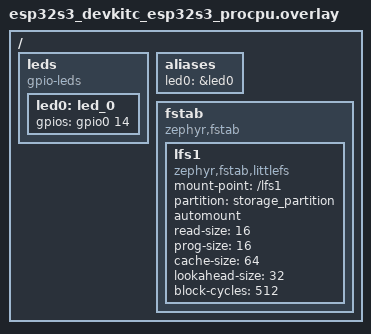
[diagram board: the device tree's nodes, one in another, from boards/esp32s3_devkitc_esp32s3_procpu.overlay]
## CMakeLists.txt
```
# Copyright (c) 2025 Golioth, Inc.
#
# SPDX-License-Identifier: Apache-2.0

cmake_minimum_required(VERSION 3.20.0)

find_package(Zephyr REQUIRED HINTS $ENV{ZEPHYR_BASE})
project(ble_gatt_example)

target_sources(app PRIVATE
  src/main.c
  src/credentials.c
  src/fatal_error.c
  src/fw_update.c
  src/ble_peripheral.c
)
```

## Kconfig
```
# Copyright (c) 2025 Golioth, Inc.
#
# SPDX-License-Identifier: Apache-2.0

config NCS_APPLICATION_BOOT_BANNER_STRING
    string
    default "Pouch BLE GATT Example"

source "$ZEPHYR_BASE/Kconfig"

config EXAMPLE_SYNC_PERIOD_S
    int "Sync Period"
    default 20
    help
      The time, in seconds, after a sync to wait before requesting a sync from
      a gateway.

config EXAMPLE_CREDENTIALS_DIR
    string "Directory containing credentials"
    default "/lfs1/credentials"
    help
      Directory on mounted file system containing credentials.
```

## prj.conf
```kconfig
# Copyright (c) 2025 Golioth, Inc.
#
# SPDX-License-Identifier: Apache-2.0

CONFIG_BT=y
CONFIG_BT_SMP=y
CONFIG_BT_PERIPHERAL=y
CONFIG_BT_DEVICE_NAME="Golioth"
CONFIG_BT_DEVICE_APPEARANCE=768

CONFIG_BT_BUF_ACL_TX_SIZE=251
CONFIG_BT_BUF_ACL_RX_SIZE=251
CONFIG_BT_L2CAP_TX_MTU=247

# This allows centrals that connect using Just Works authentication
# to re-pair. This can allow attackers to force a device to forget
# a legitimate bond. In production applications, we recommend using
# authenticated pairing, or if that is not an option, to limit the
# times when pairing is possible (e.g. by requiring user interaction
# to forget bonds or to enter pairing mode).
# We enable this option in the example app because in the absence of
# authenticated connections or another method for forcing the deletion
# of bond data, Centrals that lose their bonding information will be
# unable to reconnect.
CONFIG_BT_SMP_ALLOW_UNAUTH_OVERWRITE=y

# This is needed due to an off-by-one error in Kconfig defaults
CONFIG_BT_CTLR_DATA_LENGTH_MAX=251

CONFIG_BT_RX_STACK_SIZE=4096

CONFIG_MAIN_STACK_SIZE=4096

CONFIG_MBEDTLS_HEAP_SIZE=9192

# This option is implied by BT_SMP and breaks secp384r1 support
CONFIG_MBEDTLS_PSA_P256M_DRIVER_ENABLED=n

# Turn off default options to reduce ROM usage
CONFIG_MBEDTLS_PKCS5_C=n

CONFIG_LOG=y
CONFIG_ZCBOR=y
CONFIG_REBOOT=y
CONFIG_SHELL=y

CONFIG_POUCH=y
CONFIG_POUCH_TRANSPORT_BLE_GATT=y

CONFIG_GOLIOTH=y
CONFIG_GOLIOTH_SETTINGS=y
CONFIG_GOLIOTH_OTA=y

# Enable flash operations
CONFIG_FLASH=y
CONFIG_FLASH_MAP=y

# Enable the LittleFS file system
CONFIG_FILE_SYSTEM=y
CONFIG_FILE_SYSTEM_LITTLEFS=y
CONFIG_FILE_SYSTEM_SHELL=y

CONFIG_MCUMGR=y

# Enable console with mcumgr pass through
CONFIG_CONSOLE=y
CONFIG_UART_CONSOLE=y
CONFIG_UART_CONSOLE_MCUMGR=y

# Enable the shell mcumgr transport. This allows SMP messages to pass
# through the shell to the mgmt subsystem.
CONFIG_CRC=y
CONFIG_MCUMGR_TRANSPORT_SHELL=y

# Enable mcumgr params to allow smpmgr to query device for its MTU
CONFIG_MCUMGR_GRP_OS=y
CONFIG_MCUMGR_GRP_OS_MCUMGR_PARAMS=y

# Enable file system commands
CONFIG_MCUMGR_GRP_FS=y

CONFIG_MCUMGR_MGMT_NOTIFICATION_HOOKS=y
CONFIG_MCUMGR_GRP_FS_FILE_ACCESS_HOOK=y

CONFIG_STREAM_FLASH=y
CONFIG_IMG_MANAGER=y
CONFIG_IMG_ERASE_PROGRESSIVELY=y
```

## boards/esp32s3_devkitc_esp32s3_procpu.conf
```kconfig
CONFIG_MBEDTLS_ENABLE_HEAP=y
CONFIG_MBEDTLS_HEAP_SIZE=30000
CONFIG_BT_BUF_ACL_TX_COUNT=12
CONFIG_BT_BUF_EVT_RX_COUNT=40
CONFIG_MCUMGR_TRANSPORT_SHELL_MTU=128
```

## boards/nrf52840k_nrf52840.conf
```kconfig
CONFIG_SHELL=y
```

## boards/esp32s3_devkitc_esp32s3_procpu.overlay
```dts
/ {
    leds {
        compatible = "gpio-leds";
        led0: led_0 {
            gpios = <&gpio0 14 GPIO_ACTIVE_HIGH>;
        };
  };
    aliases {
        led0 = &led0;
    };

	fstab {
		compatible = "zephyr,fstab";
		lfs1: lfs1 {
			compatible = "zephyr,fstab,littlefs";
			mount-point = "/lfs1";
			partition = <&storage_partition>;
			automount;
			read-size = <16>;
			prog-size = <16>;
			cache-size = <64>;
			lookahead-size = <32>;
			block-cycles = <512>;
		};
	};
};
```

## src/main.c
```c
/*
 * Copyright (c) 2025 Golioth
 *
 * SPDX-License-Identifier: Apache-2.0
 */

#include <zephyr/logging/log.h>
LOG_MODULE_REGISTER(main);

#include "credentials.h"
#include "ble_peripheral.h"

#include <zephyr/drivers/gpio.h>

#include <pouch/pouch.h>
#include <pouch/events.h>
#include <pouch/uplink.h>
#include <pouch/downlink.h>
#include <pouch/transport/gatt/peripheral.h>
#include <pouch/transport/gatt/common/types.h>

#include <pouch/golioth/settings_callbacks.h>

#include <app_version.h>

static const struct gpio_dt_spec led = GPIO_DT_SPEC_GET_OR(DT_ALIAS(led0), gpios, {});
static const struct gpio_dt_spec button = GPIO_DT_SPEC_GET_OR(DT_ALIAS(sw0), gpios, {});
static struct gpio_callback button_cb_data;

/**
 * Push timeseries application data to the cloud on every uplink
 */
static void do_uplink(void)
{
    const char *data = "{\"temp\":22}";
    pouch_uplink_entry_write(".s/sensor",
                             POUCH_CONTENT_TYPE_JSON,
                             data,
                             strlen(data),
                             POUCH_FOREVER);
}

POUCH_UPLINK_HANDLER(do_uplink);

/**
 * Settings handler for the "LED" setting.
 *
 * The settings handler gets called when the Settings service
 * receives a new value for the registered setting.
 */
static int led_setting_cb(bool new_value)
{
    LOG_INF("Received LED setting: %d", (int) new_value);

    if (DT_HAS_ALIAS(led0))
    {
        gpio_pin_set_dt(&led, new_value ? 1 : 0);
    }

    return 0;
}

GOLIOTH_SETTINGS_HANDLER(LED, led_setting_cb);

/**
 * Setup pouch stack.
 *
 * Loads credentials and initializes pouch.
 */
static int setup_pouch(void)
{
    struct pouch_config config = {0};

    int err = load_certificate(&config.certificate);
    if (err)
    {
        LOG_ERR("Failed to load certificate (err %d)", err);
        return err;
    }

    config.private_key = load_private_key();
    if (config.private_key == PSA_KEY_ID_NULL)
    {
        LOG_ERR("Failed to load private key");
        return -ENOENT;
    }

    LOG_INF("Credentials loaded");

    err = pouch_init(&config);
    if (err)
    {
        LOG_ERR("Pouch init failed (err %d)", err);
        return err;
    }

    LOG_INF("Pouch initialized");
    return 0;
}

/**
 * Initialize LED.
 *
 * If the LED can't be initialized, we'll log it, but not crash out.
 * The example can still work without it.
 */
static void setup_led(void)
{
    if (!DT_HAS_ALIAS(led0))
    {
        return;
    }

    int err = gpio_pin_configure_dt(&led, GPIO_OUTPUT_ACTIVE);
    if (err < 0)
    {
        LOG_WRN("Could not initialize LED");
    }
}

/**
 * Button handler for the Bluetooth OOB authentication mechanism.
 */
static void button_pressed(const struct device *dev, struct gpio_callback *cb, uint32_t pins)
{
    ble_peripheral_button_handler();
}

/**
 * Initialize button.
 *
 * If the button can't be initialized, we'll log it, but not crash out.
 * The example can still work without it.
 */
static void setup_button(void)
{
    if (!DT_HAS_ALIAS(sw0))
    {
        return;
    }

    LOG_INF("Set up button at %s pin %d", button.port->name, button.pin);

    int err = gpio_pin_configure_dt(&button, GPIO_INPUT);
    if (err < 0)
    {
        LOG_WRN("Could not initialize Button");
        return;
    }

    err = gpio_pin_interrupt_configure_dt(&button, GPIO_INT_EDGE_TO_ACTIVE);
    if (err)
    {
        LOG_WRN("Error %d: failed to configure interrupt on %s pin %d",
                err,
                button.port->name,
                button.pin);
        return;
    }

    gpio_init_callback(&button_cb_data, button_pressed, BIT(button.pin));
    gpio_add_callback(button.port, &button_cb_data);
}

int main(void)
{
    LOG_INF("Pouch SDK Version: " STRINGIFY(APP_BUILD_VERSION));
    LOG_INF("Pouch Protocol Version: %d", POUCH_VERSION);
    LOG_INF("Pouch BLE Transport Protocol Version: %d", POUCH_GATT_VERSION);

    int err = ble_peripheral_init();
    if (err)
    {
        return err;
    }

    err = setup_pouch();
    if (err)
    {
        return err;
    }

    setup_led();
    setup_button();

    err = ble_peripheral_start();
    if (err)
    {
        return err;
    }

    LOG_INF("Advertising started");

    // Request a gateway right away:
    ble_peripheral_request_gateway(true);

    return 0;
}
```

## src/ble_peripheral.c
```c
/*
 * Copyright (c) 2026 Golioth
 *
 * SPDX-License-Identifier: Apache-2.0
 */

#include <zephyr/logging/log.h>
LOG_MODULE_REGISTER(example_ble_peripheral, LOG_LEVEL_DBG);

#include "ble_peripheral.h"

#include <zephyr/bluetooth/bluetooth.h>
#include <zephyr/bluetooth/conn.h>

#include <pouch/transport/gatt/peripheral.h>
#include <pouch/transport/gatt/common/types.h>
#include <pouch/types.h>

static struct bt_conn *default_conn;

static struct pouch_gatt_adv service_data = POUCH_GATT_ADV_DATA_INIT;

static struct bt_data ad[] = {
    BT_DATA_BYTES(BT_DATA_FLAGS, (BT_LE_AD_GENERAL | BT_LE_AD_NO_BREDR)),
    BT_DATA(BT_DATA_SVC_DATA16, &service_data, sizeof(service_data)),
    BT_DATA(BT_DATA_NAME_COMPLETE, CONFIG_BT_DEVICE_NAME, sizeof(CONFIG_BT_DEVICE_NAME) - 1),
};

static void connected(struct bt_conn *conn, uint8_t err)
{
    if (err)
    {
        LOG_DBG("Connection failed (err 0x%02x)", err);
        return;
    }

    LOG_DBG("Connected");
    default_conn = conn;
}

static void sync_request_work_handler(struct k_work *work)
{
    LOG_DBG("Requesting Gateway sync");
    ble_peripheral_request_gateway(true);
}
K_WORK_DELAYABLE_DEFINE(sync_request_work, sync_request_work_handler);

static void resume_advertising(struct k_work *work)
{
    int err = ble_peripheral_start();
    if (err)
    {
        LOG_ERR("Failed to start advertising (err: %d)", err);
        return;
    }

    // Although advertising resumes right away, we don't have to request a gateway.
    // Schedule the gateway flag to be set at a later time:
    k_work_schedule(&sync_request_work, K_SECONDS(CONFIG_EXAMPLE_SYNC_PERIOD_S));
}
K_WORK_DEFINE(resume_work, resume_advertising);

static void disconnected(struct bt_conn *conn, uint8_t reason)
{
    LOG_DBG("Disconnected (reason 0x%02x)", reason);

    default_conn = NULL;
    k_work_submit(&resume_work);
}

BT_CONN_CB_DEFINE(conn_callbacks) = {
    .connected = connected,
    .disconnected = disconnected,
};

static void auth_passkey_display(struct bt_conn *conn, unsigned int passkey)
{
    char addr[BT_ADDR_LE_STR_LEN];
    char passkey_str[7];

    bt_addr_le_to_str(bt_conn_get_dst(conn), addr, sizeof(addr));

    (void) snprintf(passkey_str, sizeof(passkey_str), "%06u", passkey);

    LOG_INF("Passkey for %s: %s", addr, passkey_str);
}

static void auth_passkey_confirm(struct bt_conn *conn, unsigned int passkey)
{
    char addr[BT_ADDR_LE_STR_LEN];
    char passkey_str[7];

    bt_addr_le_to_str(bt_conn_get_dst(conn), addr, sizeof(addr));

    (void) snprintf(passkey_str, sizeof(passkey_str), "%06u", passkey);

    LOG_INF("Confirm passkey for %s: %s", addr, passkey_str);

    if (IS_ENABLED(CONFIG_EXAMPLE_BT_AUTO_CONFIRM))
    {
        LOG_INF("Confirming passkey");
        bt_conn_auth_passkey_confirm(conn);
    }
}

static void auth_cancel(struct bt_conn *conn)
{
    char addr[BT_ADDR_LE_STR_LEN];

    bt_addr_le_to_str(bt_conn_get_dst(conn), addr, sizeof(addr));

    LOG_INF("Pairing cancelled: %s", addr);
}

static struct bt_conn_auth_cb auth_cb_display = {
    .passkey_display = auth_passkey_display,
    .passkey_confirm = auth_passkey_confirm,
    .cancel = auth_cancel,
};

void ble_peripheral_request_gateway(bool request)
{
    pouch_gatt_adv_req_sync(&service_data, request);
    bt_le_adv_update_data(ad, ARRAY_SIZE(ad), NULL, 0);
}

void ble_peripheral_button_handler(void)
{
    if (default_conn)
    {
        LOG_INF("Confirming passkey");
        bt_conn_auth_passkey_confirm(default_conn);
    }
    else
    {
        LOG_WRN("No BT connection for passkey confirmation");
    }
}

int ble_peripheral_init(void)
{
    int err = pouch_gatt_peripheral_init();
    if (err)
    {
        LOG_ERR("Failed to initialize Pouch BLE GATT peripheral (err %d)", err);
        return err;
    }

    err = bt_enable(NULL);
    if (err)
    {
        LOG_ERR("Bluetooth init failed (err %d)", err);
        return err;
    }

    err = bt_conn_auth_cb_register(&auth_cb_display);
    if (err)
    {
        LOG_ERR("Bluetooth auth cb register failed (err %d)", err);
        return err;
    }

    return 0;
}

int ble_peripheral_start(void)
{
    pouch_gatt_adv_req_sync(&service_data, false);
    return bt_le_adv_start(BT_LE_ADV_CONN_FAST_2, ad, ARRAY_SIZE(ad), NULL, 0);
}
```

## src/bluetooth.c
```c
/*
 * Copyright (c) 2026 Golioth
 *
 * SPDX-License-Identifier: Apache-2.0
 */

#include <zephyr/logging/log.h>
LOG_MODULE_REGISTER(example_bt);

#include "bluetooth.h"

#include <zephyr/bluetooth/bluetooth.h>
#include <zephyr/bluetooth/conn.h>

#include <pouch/transport/gatt/peripheral.h>
#include <pouch/transport/gatt/common/types.h>
#include <pouch/types.h>

static struct bt_conn *default_conn;

static struct pouch_gatt_adv service_data = POUCH_GATT_ADV_DATA_INIT;

static struct bt_data ad[] = {
    BT_DATA_BYTES(BT_DATA_FLAGS, (BT_LE_AD_GENERAL | BT_LE_AD_NO_BREDR)),
    BT_DATA(BT_DATA_SVC_DATA16, &service_data, sizeof(service_data)),
    BT_DATA(BT_DATA_NAME_COMPLETE, CONFIG_BT_DEVICE_NAME, sizeof(CONFIG_BT_DEVICE_NAME) - 1),
};

static void connected(struct bt_conn *conn, uint8_t err)
{
    if (err)
    {
        LOG_DBG("Connection failed (err 0x%02x)", err);
        return;
    }

    LOG_DBG("Connected");
    default_conn = conn;
}

static void disconnected(struct bt_conn *conn, uint8_t reason)
{
    LOG_DBG("Disconnected (reason 0x%02x)", reason);

    default_conn = NULL;
    bluetooth_start();
}

BT_CONN_CB_DEFINE(conn_callbacks) = {
    .connected = connected,
    .disconnected = disconnected,
};

static void auth_passkey_display(struct bt_conn *conn, unsigned int passkey)
{
    char addr[BT_ADDR_LE_STR_LEN];
    char passkey_str[7];

    bt_addr_le_to_str(bt_conn_get_dst(conn), addr, sizeof(addr));

    (void) snprintf(passkey_str, sizeof(passkey_str), "%06u", passkey);

    LOG_INF("Passkey for %s: %s", addr, passkey_str);
}

static void auth_passkey_confirm(struct bt_conn *conn, unsigned int passkey)
{
    char addr[BT_ADDR_LE_STR_LEN];
    char passkey_str[7];

    bt_addr_le_to_str(bt_conn_get_dst(conn), addr, sizeof(addr));

    (void) snprintf(passkey_str, sizeof(passkey_str), "%06u", passkey);

    LOG_INF("Confirm passkey for %s: %s", addr, passkey_str);

    if (IS_ENABLED(CONFIG_EXAMPLE_BT_AUTO_CONFIRM))
    {
        LOG_INF("Confirming passkey");
        bt_conn_auth_passkey_confirm(conn);
    }
}

static void auth_cancel(struct bt_conn *conn)
{
    char addr[BT_ADDR_LE_STR_LEN];

    bt_addr_le_to_str(bt_conn_get_dst(conn), addr, sizeof(addr));

    LOG_INF("Pairing cancelled: %s", addr);
}

static struct bt_conn_auth_cb auth_cb_display = {
    .passkey_display = auth_passkey_display,
    .passkey_confirm = auth_passkey_confirm,
    .cancel = auth_cancel,
};

void bluetooth_request_gateway(bool request)
{
    pouch_gatt_adv_req_sync(&service_data, request);
    bt_le_adv_update_data(ad, ARRAY_SIZE(ad), NULL, 0);
}

void bluetooth_button_handler(void)
{
    if (default_conn)
    {
        LOG_INF("Confirming passkey");
        bt_conn_auth_passkey_confirm(default_conn);
    }
    else
    {
        LOG_WRN("No BT connection for passkey confirmation");
    }
}

int bluetooth_init(void)
{
    int err = pouch_gatt_peripheral_init();
    if (err)
    {
        LOG_ERR("Failed to initialize Pouch BLE GATT peripheral (err %d)", err);
        return err;
    }

    err = bt_enable(NULL);
    if (err)
    {
        LOG_ERR("Bluetooth init failed (err %d)", err);
        return err;
    }

    err = bt_conn_auth_cb_register(&auth_cb_display);
    if (err)
    {
        LOG_ERR("Bluetooth auth cb register failed (err %d)", err);
        return err;
    }

    return 0;
}

int bluetooth_start(void)
{
    pouch_gatt_adv_req_sync(&service_data, false);
    return bt_le_adv_start(BT_LE_ADV_CONN_FAST_2, ad, ARRAY_SIZE(ad), NULL, 0);
}
```

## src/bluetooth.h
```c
/*
 * Copyright (c) 2026 Golioth, Inc.
 *
 * SPDX-License-Identifier: Apache-2.0
 */
#pragma once

#include <stdint.h>
#include <stddef.h>
#include <stdbool.h>

/**
 * Button handler for Bluetooth OOB authentication.
 */
void bluetooth_button_handler(void);

/**
 * Enable or disable the gateway request flag in the Bluetooth advertisements.
 */
void bluetooth_request_gateway(bool request);

/**
 * Initialize application Bluetooth module.
 */
int bluetooth_init(void);

/**
 * Start Bluetooth advertising.
 */
int bluetooth_start(void);
```

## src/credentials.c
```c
/*
 * Copyright (c) 2025 Golioth, Inc.
 *
 * SPDX-License-Identifier: Apache-2.0
 */
#include <stdlib.h>
#include <zephyr/fs/fs.h>
#include <pouch/pouch.h>
#include <mbedtls/pk.h>

#include <zephyr/logging/log.h>
LOG_MODULE_REGISTER(credentials);

#define CERT_DIR CONFIG_EXAMPLE_CREDENTIALS_DIR
#define CERT_FILE CERT_DIR "/crt.der"
#define KEY_FILE CERT_DIR "/key.der"

static int psa_rng_for_mbedtls(void *p_rng, unsigned char *output, size_t output_len)
{
    return psa_generate_random(output, output_len);
}

/** Load the raw private key data into PSA */
static psa_key_id_t import_raw_pk(const uint8_t *private_key, size_t size)
{
    mbedtls_pk_context pk;
    mbedtls_pk_init(&pk);
    int err = mbedtls_pk_parse_key(&pk, private_key, size, NULL, 0, psa_rng_for_mbedtls, NULL);
    if (err)
    {
        LOG_ERR("Failed to parse key: -0x%x", -err);
        return PSA_KEY_ID_NULL;
    }

    psa_key_attributes_t attrs = PSA_KEY_ATTRIBUTES_INIT;

    psa_set_key_algorithm(&attrs, PSA_ALG_ECDH);
    psa_set_key_type(&attrs, PSA_KEY_TYPE_ECC_KEY_PAIR(PSA_ECC_FAMILY_SECP_R1));
    psa_set_key_usage_flags(&attrs, PSA_KEY_USAGE_DERIVE);

    psa_key_id_t key_id;
    err = mbedtls_pk_import_into_psa(&pk, &attrs, &key_id);
    if (err)
    {
        LOG_ERR("Failed to import private key: -0x%x", -err);
        return PSA_KEY_ID_NULL;
    }

    return key_id;
}

static void ensure_credentials_dir(void)
{
    struct fs_dirent dirent;

    int err = fs_stat(CERT_DIR, &dirent);
    if (err == -ENOENT)
    {
        err = fs_mkdir(CERT_DIR);
    }

    if (err)
    {
        LOG_ERR("Failed to create credentials dir: %d", err);
    }
}

static ssize_t get_file_size(const char *path)
{
    struct fs_dirent dirent;

    int err = fs_stat(path, &dirent);

    if (err < 0)
    {
        return err;
    }
    if (dirent.type != FS_DIR_ENTRY_FILE)
    {
        return -EISDIR;
    }

    return dirent.size;
}

static ssize_t read_file(const char *path, uint8_t **out)
{
    // Ensure that the credentials directory exists, so the user doesn't have to
    ensure_credentials_dir();

    ssize_t size = get_file_size(path);
    if (size <= 0)
    {
        return size;
    }

    uint8_t *buf = malloc(size);
    if (buf == NULL)
    {
        return -ENOMEM;
    }

    struct fs_file_t file;
    fs_file_t_init(&file);

    int err = fs_open(&file, path, FS_O_READ);
    if (err)
    {
        LOG_ERR("Could not open %s, err: %d", path, err);
        free(buf);
        return err;
    }

    size = fs_read(&file, buf, size);
    if (size < 0)
    {
        LOG_ERR("Could not read %s, err: %d", path, size);
        free(buf);
        goto finish;
    }

    LOG_DBG("Read %d bytes from %s", size, path);

    *out = buf;

finish:
    fs_close(&file);
    return size;
}

psa_key_id_t load_private_key(void)
{
    uint8_t *buf;
    ssize_t size = read_file(KEY_FILE, &buf);
    if (size < 0)
    {
        return PSA_KEY_ID_NULL;
    }

    psa_key_id_t key_id = import_raw_pk(buf, size);
    free(buf);
    return key_id;
}

int load_certificate(struct pouch_cert *cert)
{
    uint8_t *buf;
    ssize_t size = read_file(CERT_FILE, &buf);
    if (size < 0)
    {
        return size;
    }

    cert->buffer = buf;
    cert->size = size;

    LOG_DBG("Read certificate (%d bytes)", size);

    return 0;
}

void free_certificate(struct pouch_cert *cert)
{
    free((void *) cert->buffer);
}
```

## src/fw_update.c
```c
/*
 * Copyright (c) 2025 Golioth
 *
 * SPDX-License-Identifier: Apache-2.0
 */

#include <zephyr/logging/log.h>
LOG_MODULE_REGISTER(fw_update);

#include <zephyr/kernel.h>
#include <zephyr/dfu/flash_img.h>
#include <zephyr/dfu/mcuboot.h>
#include <zephyr/logging/log_ctrl.h>
#include <zephyr/storage/flash_map.h>
#include <zephyr/sys/reboot.h>

#include <golioth/ota.h>

#include <app_version.h>

static struct flash_img_context flash_context;

static void ota_main_receive(const void *data, size_t offset, size_t len, bool is_last)
{
    LOG_DBG("Received %d bytes at offset %d", len, offset);

    int err = 0;

    if (0 == offset)
    {
        err = flash_img_init(&flash_context);
        if (err)
        {
            LOG_ERR("Failed to init flash write");
            return;
        }
    }

    err = flash_img_buffered_write(&flash_context, data, len, is_last);
    if (err)
    {
        LOG_ERR("Failed to write to flash: %d", err);
        return;
    }

    if (is_last)
    {
        err = boot_request_upgrade(BOOT_UPGRADE_PERMANENT);
        if (err)
        {
            LOG_ERR("Failed to request upgrade");
            return;
        }

        LOG_INF("Rebooting to apply upgrade");
        while (log_process())
        {
        }

        k_sleep(K_SECONDS(3));

        sys_reboot(SYS_REBOOT_WARM);
    }
}

static void ota_manifest_receive(const struct golioth_ota_manifest_component *components,
                                 size_t num_components)
{
    for (int i = 0; i < num_components; i++)
    {
        LOG_DBG("Target: %s@%s, %d bytes",
                components[i].name,
                components[i].target,
                components[i].size);
        LOG_HEXDUMP_DBG(components[i].target_hash,
                        GOLIOTH_OTA_COMPONENT_HASH_BIN_LEN,
                        "Target hash:");
        if (0 != strcmp(components[i].current, components[i].target))
        {
            golioth_ota_mark_for_download(components[i].name);
        }
    }
}

GOLIOTH_OTA_COMPONENT(main, "main", APP_VERSION_STRING, ota_main_receive);
GOLIOTH_OTA_MANIFEST_HANDLER(ota_manifest_receive);
```
